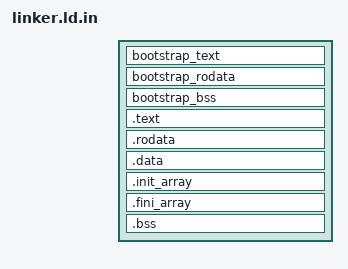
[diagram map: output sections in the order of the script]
/***
 *                                                                                      
 *      ,ad8888ba,    ,ad8888ba,    88888888ba         db         88      888888888888  
 *     d8"'    `"8b  d8"'    `"8b   88      "8b       d88b        88           88       
 *    d8'           d8'        `8b  88      ,8P      d8'`8b       88           88       
 *    88            88          88  88aaaaaa8P'     d8'  `8b      88           88       
 *    88            88          88  88""""""8b,    d8YaaaaY8b     88           88       
 *    Y8,           Y8,        ,8P  88      `8b   d8""""""""8b    88           88       
 *     Y8a.    .a8P  Y8a.    .a8P   88      a8P  d8'        `8b   88           88       
 *      `"Y8888Y"'    `"Y8888Y"'    88888888P"  d8'          `8b  88888888888  88       
 *  Cobalt is a UNIX-like operating system forked from Dennis Wölfing's Dennix operating
 *  system, which can be found at https://github.com/dennis95/dennix. Cobalt is licensed
 *  under the ISC license, which can be found at the file called LICENSE at the root
 *  directory of the project.
 */

#include <cobalt/kernel/arch.h>

ENTRY(_start);

SECTIONS {
    . = KERNEL_PHYSICAL;

    bootstrapBegin = .;

    bootstrap_text : {
        *(multiboot)
        *(bootstrap_text)
    }
    bootstrap_rodata : {
        *(bootstrap_rodata)
        . = ALIGN(4096);
    }

    bootstrap_bss ALIGN(4096) : {
        *(bootstrap_bss)
        . = ALIGN(4096);
    }

    bootstrapEnd = .;
    numBootstrapPages = (bootstrapEnd - bootstrapBegin) / 0x1000;

    . += KERNEL_VIRTUAL;

    kernelVirtualBegin = ALIGN(4096);
    kernelPhysicalBegin = kernelVirtualBegin - KERNEL_VIRTUAL;

    .text : AT(ADDR(.text) - KERNEL_VIRTUAL) {
        *(.text.unlikely)
        *(.text.exit)
        *(.text.startup)
        *(.text*)
    }

    kernelExecEnd = ALIGN(4096);
    numExecPages = (kernelExecEnd - kernelVirtualBegin) / 0x1000;

    .rodata ALIGN(4096) : AT(ADDR(.rodata) - KERNEL_VIRTUAL) {
        *(.rodata*)
        . = ALIGN(4096);
    }

    kernelReadOnlyEnd = .;
    numReadOnlyPages = (kernelReadOnlyEnd - kernelVirtualBegin) / 0x1000;

    .data ALIGN(4096) : AT(ADDR(.data) - KERNEL_VIRTUAL) {
        *(.data)
    }

    .init_array : AT(ADDR(.init_array) - KERNEL_VIRTUAL) {
        __init_array_start = .;
        KEEP(*(SORT_BY_INIT_PRIORITY(.init_array.*)))
        KEEP(*(.init_array))
        __init_array_end = .;
    }

    .fini_array : AT(ADDR(.fini_array) - KERNEL_VIRTUAL) {
        __fini_array_start = .;
        KEEP(*(SORT_BY_INIT_PRIORITY(.fini_array.*)))
        KEEP(*(.fini_array))
        __fini_array_end = .;
    }

    .bss ALIGN(4096) : AT(ADDR(.bss) - KERNEL_VIRTUAL) {
        *(.bss)
        . = ALIGN(4096);
    }

    kernelVirtualEnd = .;
    kernelPhysicalEnd = kernelVirtualEnd - KERNEL_VIRTUAL;
    numWritablePages = (kernelVirtualEnd - kernelReadOnlyEnd) / 0x1000;

    ASSERT(kernelPhysicalEnd <= 0x400000, "kernel too big")
}
